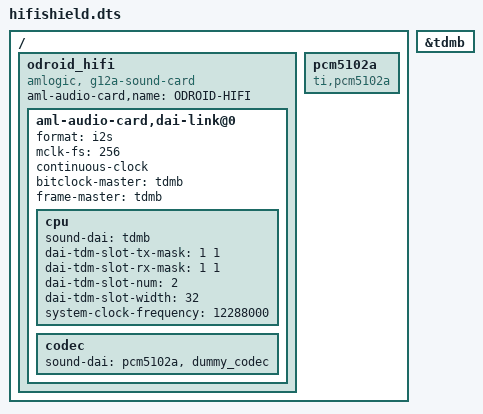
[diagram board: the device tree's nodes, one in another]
/dts-v1/;
/plugin/;

/ {
	fragment@0 {
		target = <&tdmb>;
		__overlay__ {
			status = "okay";
		};
	};

	fragment@1 {
		target-path = "/";

		__overlay__ {
			odroid_hifi: odroid_hifi {
				compatible = "amlogic, g12a-sound-card";
				aml-audio-card,name = "ODROID-HIFI";
				status = "okay";

				/* ODROID-C4: I2S out(J7)*/
				aml-audio-card,dai-link@0 {
					format = "i2s";
					mclk-fs = <256>;
					continuous-clock;
					bitclock-master = <&tdmb>;
					frame-master = <&tdmb>;
					cpu {
						sound-dai = <&tdmb>;
						dai-tdm-slot-tx-mask = <1 1>;
						dai-tdm-slot-rx-mask = <1 1>;
						dai-tdm-slot-num = <2>;
						dai-tdm-slot-width = <32>;
						system-clock-frequency = <12288000>;
					};
					codec {
						sound-dai = <&pcm5102a &dummy_codec>;
					};
				};
			};

			pcm5102a: pcm5102a {
				compatible = "ti,pcm5102a";
				#sound-dai-cells = <0>;
				status = "okay";
			};
		};
	};
};
